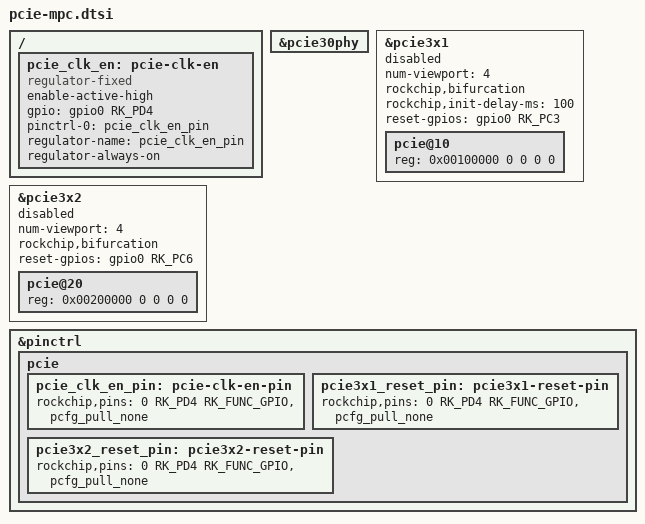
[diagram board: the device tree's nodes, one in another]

/*
	This controller has one lane 1.
	The lane 1 can be switched between X18(m.2B/M) and D8(WGI210AT). This depends on ETH_PCIE_SEL (D14 switch) signal state.
	If bifurcation mode is cativated the lane 1 is controlled by pcie3x1.
	To suplpy X18 with lane 1 signals it needs to set ETH_PCIE_SEL=1.
	To suplpy D8 with lane 1 signals it needs to set ETH_PCIE_SEL=1.
	ETH_PCIE_SEL signal is pulled up via R178, and pulled down via R102.
*/

/{
/*
	This is dummy regulator.
	It is used to have ability to activate PCIE clocks
*/
	pcie_clk_en: pcie-clk-en {
		compatible = "regulator-fixed";
		enable-active-high;
		// 1V8_PCIE_PWREN
		gpio = <&gpio0 RK_PD4 GPIO_ACTIVE_HIGH>;
		pinctrl-names = "default";
		pinctrl-0 = <&pcie_clk_en_pin>;
		regulator-name = "pcie_clk_en_pin";
		regulator-always-on;
    };
/*
	1V8_PCIE_PWREN -> VT14(NMOS)->PCIe_EN_ -> VT15 (PMOS) -> +3.3v2_M2_CON
	0 -> 1 -> 0
	1 -> 0 -> 1

	+3.3v2_M2_CON supplies device connected to X18 (m.2 B/M)

	1V8_PCIE_PWREN -> VT14(NMOS)->PCIe_EN_ -> VT28 (PMOS) -> +3.3vPCIe
	0 -> 1 -> 0
	1 -> 0 -> 1

	+3.3vPCIe supplies D8 (SFP) and activtes generating PCIE30_REFCLKP/PCIE30_REFCLKN (reference clocks for PCIE3x controller) clocks

	D14 multiplexor is responsible for switching PCIE30_TX1P/PCIE30_TX1N and PCIE30_RX1P/PCIE30_RX1N between X18 and D8(SFP)
*/
};

&pcie30phy {
	status = "okay";
};

/*
	This controller has one lane 1.
	The lane 1 can be switched between X18(m.2B/M) and D8(WGI210AT). This depends on ETH_PCIE_SEL (D14 switch) signal state.
	If bifurcation mode is cativated the lane 1 is controlled by pcie3x1.
	To suplpy X18 with lane 1 signals it needs to set ETH_PCIE_SEL=1.
	To suplpy D8 with lane 1 signals it needs to set ETH_PCIE_SEL=1.
	ETH_PCIE_SEL signal is pulled up via R178, and pulled down via R102.
*/
&pcie3x1 {
	num-viewport = <4>;
	rockchip,bifurcation;
	rockchip,init-delay-ms = <100>;
/*
	PCIE30X1_PERSTn -> R115(0) -> D8
	0 -> 0
	1 -> 1
*/
	reset-gpios = <&gpio0 RK_PC3 GPIO_ACTIVE_HIGH>;

	status = "disabled";

	pcie@10 {
		reg = <0x00100000 0 0 0 0>;
		#address-cells = <3>;
		#size-cells = <2>;

/*		r8125_2: pcie@10,0 {
			reg = <0x000000 0 0 0 0>;
			local-mac-address = [ 00 00 00 00 00 00 ];
		};*/
	};
};

/*
	This controller has two lanes which can be organized in PCIE2x mode or in case of enabled bifurcation in PCIE1x mode.
	The lane 0 an 1 connected to X18(m.2B).
	The lane 1 can be switched between X18(m.2B/M) and D8(WGI210AT). This depends on ETH_PCIE_SEL (D14 switch) signal state.
	If bifurcation mode is cativated the lane 1 is controlled by pcie3x1.
	To suplpy X18 with lane 1 signals it needs to set ETH_PCIE_SEL=1.
	To suplpy D8 with lane 1 signals it needs to set ETH_PCIE_SEL=1.
	ETH_PCIE_SEL signal is pulled up via R178, and pulled down via R102.
*/
&pcie3x2 {
	num-viewport = <4>;
	rockchip,bifurcation;
/*
	PCIE30X2_PERSTn is pulled up to +3.3vPCIe via R116(10K)
	PCIE30X2_PERSTn -> R179(0) -> M2_PCIE_RSTn (X18 m.2 B/M PERST#)
	0 -> 0
	1 -> 1
*/
	reset-gpios = <&gpio0 RK_PC6 GPIO_ACTIVE_HIGH>;

	status = "disabled";

	pcie@20 {
		reg = <0x00200000 0 0 0 0>;
		#address-cells = <3>;
		#size-cells = <2>;

/*		r8125_1: pcie@20,0 {
			reg = <0x000000 0 0 0 0>;
			local-mac-address = [ 00 00 00 00 00 00 ];
		};*/
	};
};

&pinctrl {
	pcie {
		pcie_clk_en_pin: pcie-clk-en-pin {
			// 1V8_PCIE_PWREN
			rockchip,pins = <0 RK_PD4 RK_FUNC_GPIO &pcfg_pull_none>;
		};

		pcie3x1_reset_pin: pcie3x1-reset-pin {
/*
			PCIE30X1_PERSTn -> R115(0) -> D8
			0 -> 0
			1 -> 1
*/
			rockchip,pins = <0 RK_PD4 RK_FUNC_GPIO &pcfg_pull_none>;
		};

		pcie3x2_reset_pin: pcie3x2-reset-pin {
/*
			PCIE30X2_PERSTn is pulled up to +3.3vPCIe via R116(10K)
			PCIE30X2_PERSTn -> R179(0) -> M2_PCIE_RSTn (X18 m.2 B/M PERST#)
			0 -> 0
			1 -> 1
*/
			rockchip,pins = <0 RK_PD4 RK_FUNC_GPIO &pcfg_pull_none>;
		};
	};
};

